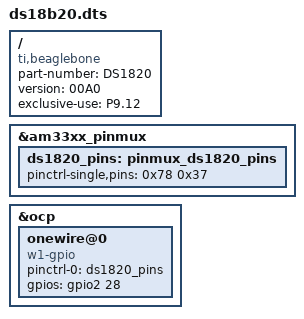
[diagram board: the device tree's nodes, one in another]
/*
* Copyright (C) 2012 Texas Instruments Incorporated - http://www.ti.com/
*
* This program is free software; you can redistribute it and/or modify
* it under the terms of the GNU General Public License version 2 as
* published by the Free Software Foundation.
* 
* Modified  by Russell Senior from the weather cape's DTS file.
* Minor formatting by C W Rose.
*/
/dts-v1/;
/plugin/;

/ {
    compatible = "ti,beaglebone", "ti,beaglebone-black";
    part-number = "DS1820";
    version = "00A0";

    exclusive-use = "P9.12";

    fragment@0 {
        target = <&am33xx_pinmux>;
        __overlay__ {
             ds1820_pins: pinmux_ds1820_pins {
                 pinctrl-single,pins =  <0x78 0x37 /* gpmc_be1n.gpio1_28, OMAP_PIN_INPUT_PULLUP | OMAP_MUX_MODE7 - w1-gpio */ >;
             };
        };
    };

    fragment@1 {
        target = <&ocp>;
        __overlay__ {
            onewire@0 {
                status          = "okay";
                compatible      = "w1-gpio";
                pinctrl-names   = "default";
                pinctrl-0       = <&ds1820_pins>;

                gpios = <&gpio2 28 0>;
            };
        };
    };
};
